# STM32WBA50xx register map
File version: 1.0
Registers are 32-bit, read-write, reset 0x0 unless marked. A register's access mark holds for its fields unless they carry their own. Offsets are from the block's base; [hi:lo] are bit positions; lines under a group give offsets from that group; {n}, {i} and the like mark numbered series; 'fields as' and 'values as' point back to an identical list.

## CRC — CRC calculation unit
Base 0x40023000
0x00 DR — CRC Data register
  [31:0] DR — Data register bits
0x04 IDR — CRC Independent data register
  [31:0] IDR — General-purpose 32-bits data register bits
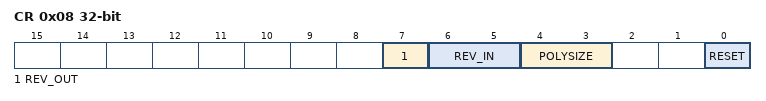
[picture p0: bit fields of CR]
0x08 CR — CRC Control register
  [7] REV_OUT — REV_OUT Reverse Output Data bits
    0=NONE (Output Data bit order not affected); 1=BIT (Output Data bit reversal done by bit)
  [6:5] REV_IN — REV_IN Reverse Input Data bits
    0=NONE (Input Data bit order not affected); 1=BYTE (Input Data bit reversal done by byte); 2=HALFWORD (Input Data bit reversal done by half-word); 3=WORD (Input Data bit reversal done by word)
  [4:3] POLYSIZE — Polynomial size bits
    0=POLYLENGTH_32B (32 bits Polynomial size); 1=POLYLENGTH_16B (16 bits Polynomial size); 2=POLYLENGTH_8B (8 bits Polynomial size); 3=POLYLENGTH_7B (7 bits Polynomial size)
  [0] RESET — RESET the CRC computation unit bit
0x10 INIT — Initial CRC value register
  [31:0] INIT — Initial CRC value bits
0x14 POL — CRC polynomial register
  [31:0] POL — Coefficients of the polynomial

## TSC
Base 0x40024000
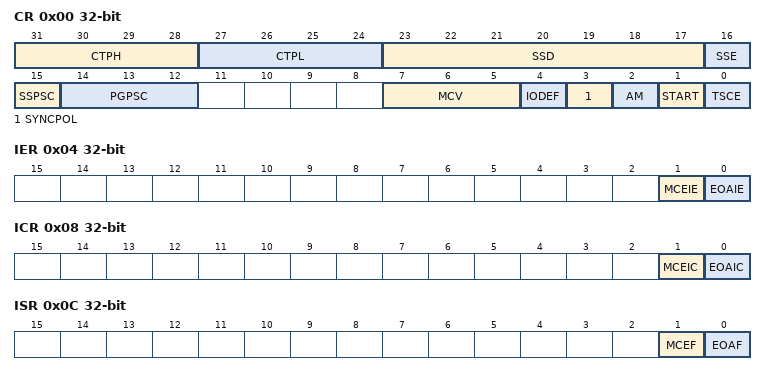
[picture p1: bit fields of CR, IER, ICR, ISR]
0x00 CR — TSC Control register
  [31:28] CTPH — CTPH[3:0] bits (Charge Transfer pulse high)
  [27:24] CTPL — CTPL[3:0] bits (Charge Transfer pulse low)
  [23:17] SSD — SSD[6:0] bits (Spread Spectrum Deviation)
  [16] SSE — Spread Spectrum Enable
  [15] SSPSC — Spread Spectrum Prescaler
  [14:12] PGPSC — PGPSC[2:0] bits (Pulse Generator Prescaler)
  [7:5] MCV — MCV[2:0] bits (Max Count Value)
  [4] IODEF — IO default mode
  [3] SYNCPOL — Synchronization pin polarity
  [2] AM — Acquisition mode
  [1] START — Start acquisition
  [0] TSCE — Touch sensing controller enable
0x04 IER — TSC Interrupt Enable register
  [1] MCEIE — Max count error interrupt enable
  [0] EOAIE — End of acquisition interrupt enable
0x08 ICR — TSC Interrupt Control register
  [1] MCEIC — Max count error interrupt clear
  [0] EOAIC — End of acquisition interrupt clear
0x0C ISR — TSC Interrupt Status register
  [1] MCEF — Max count error flag
  [0] EOAF — End of acquisition flag
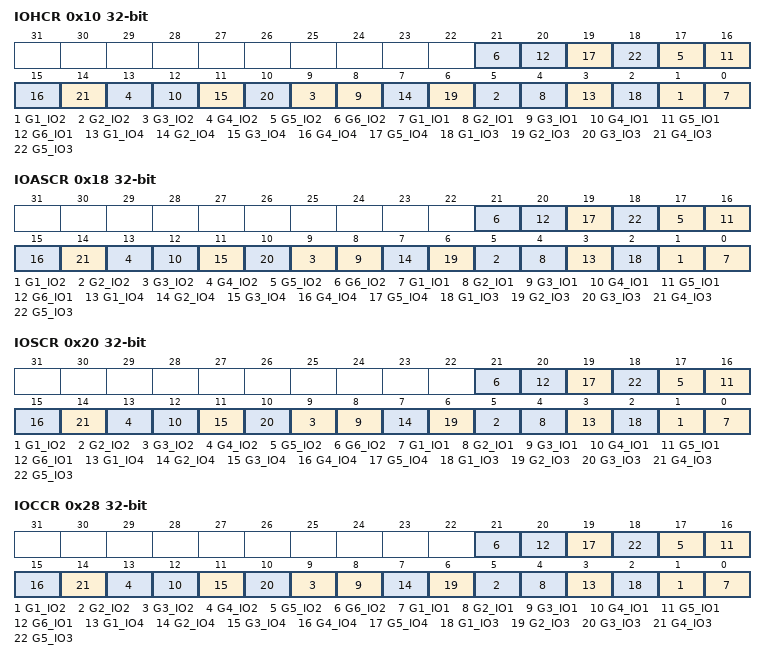
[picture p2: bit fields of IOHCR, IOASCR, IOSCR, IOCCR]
0x10 IOHCR — TSC I/O hysteresis control register
  [4n-3] G{n}_IO2 (n=1..6) — GROUP{n}_IO2 schmitt trigger hysteresis mode
  [4n-4] G{n}_IO1 (n=1..6) — GROUP{n}_IO1 schmitt trigger hysteresis mode
  [4n-1] G{n}_IO4 (n=1..5) — GROUP{n}_IO4 schmitt trigger hysteresis mode
  [4n-2] G{n}_IO3 (n=1..5) — GROUP{n}_IO3 schmitt trigger hysteresis mode
0x18 IOASCR — TSC I/O analog switch control register
  [4n-3] G{n}_IO2 (n=1..6) — GROUP{n}_IO2 analog switch enable
  [4n-4] G{n}_IO1 (n=1..6) — GROUP{n}_IO1 analog switch enable
  [4n-1] G{n}_IO4 (n=1..5) — GROUP{n}_IO4 analog switch enable
  [4n-2] G{n}_IO3 (n=1..5) — GROUP{n}_IO3 analog switch enable
0x20 IOSCR — TSC I/O sampling control register
  [4n-3] G{n}_IO2 (n=1..6) — GROUP{n}_IO2 sampling mode
  [4n-4] G{n}_IO1 (n=1..6) — GROUP{n}_IO1 sampling mode
  [4n-1] G{n}_IO4 (n=1..5) — GROUP{n}_IO4 sampling mode
  [4n-2] G{n}_IO3 (n=1..5) — GROUP{n}_IO3 sampling mode
0x28 IOCCR — TSC I/O channel control register
  [4n-3] G{n}_IO2 (n=1..6) — GROUP{n}_IO2 channel mode
  [4n-4] G{n}_IO1 (n=1..6) — GROUP{n}_IO1 channel mode
  [4n-1] G{n}_IO4 (n=1..5) — GROUP{n}_IO4 channel mode
  [4n-2] G{n}_IO3 (n=1..5) — GROUP{n}_IO3 channel mode
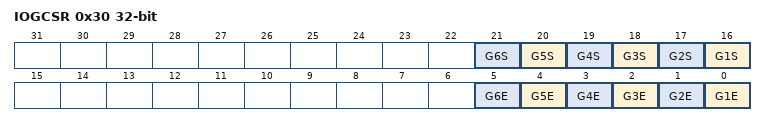
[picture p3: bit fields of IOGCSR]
0x30 IOGCSR — TSC I/O group control status register
  [n+15] G{n}S (n=1..6) — Analog IO GROUP{n} status
  [n-1] G{n}E (n=1..6) — Analog IO GROUP{n} enable
{0x30+4i} IOG{i}CR (i=1..6) — TSC I/O group x counter register
  [13:0] CNT — CNT[13:0] bits (Counter value)

## RAMCFG
Base 0x40026000
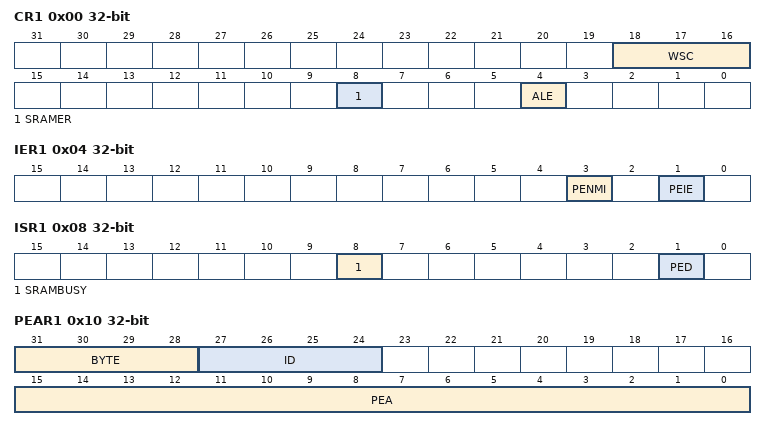
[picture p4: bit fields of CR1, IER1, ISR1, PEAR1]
0x00 CR1 — Control Register
  [18:16] WSC — WSC[18:16] Wait State Configuration field
  [8] SRAMER — Start Erase
  [4] ALE — Address Latching Enable
0x04 IER1 — Interrupt enable register
  [3] PENMI — Parity error NMI
  [1] PEIE — Parity error interrupt enable
0x08 ISR1 — Interrupt status register
  [8] SRAMBUSY — SRAM busy with erase operation
  [1] PED — Parity error detected
0x10 PEAR1 — Parity error address register
  [31:28] BYTE — Byte parity error flag
  [27:24] ID — Parity error AHB bus master ID
  [15:0] PEA — Parity error SRAM word aligned address offset
0x14 ICR1 — Interrupt clear register
  [1] CPED — Clear parity error detect bit
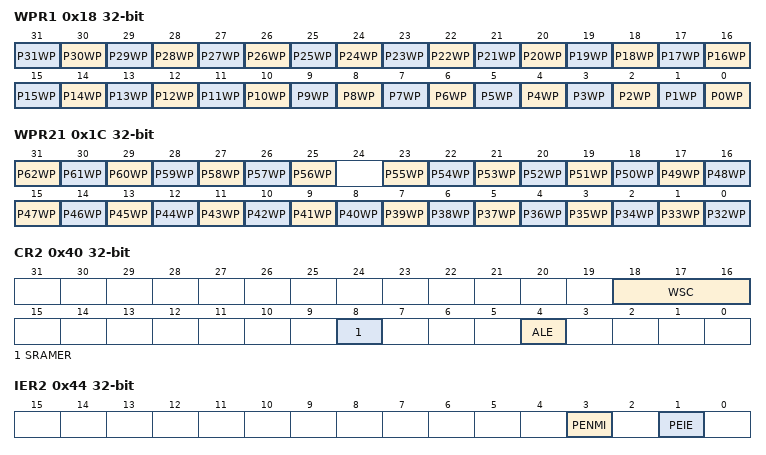
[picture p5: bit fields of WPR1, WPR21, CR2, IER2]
0x18 WPR1 — Write protection register 1
  [n] P{n}WP (n=0..31) — Write Protection Page {n:02}
0x1C WPR21 — Write protection register 2
  [n-31] P{n}WP (n=56..62) — Write Protection Page {n}
  [n-32] P{n}WP (n=32..55) — Write Protection Page {n}
0x28 ERKEYR1 — Erase key register
  [7:0] ERASEKEY — Erase write protection key
0x40 CR2 — Control Register
  fields as CR1
0x44 IER2 — Interrupt enable register
  fields as IER1
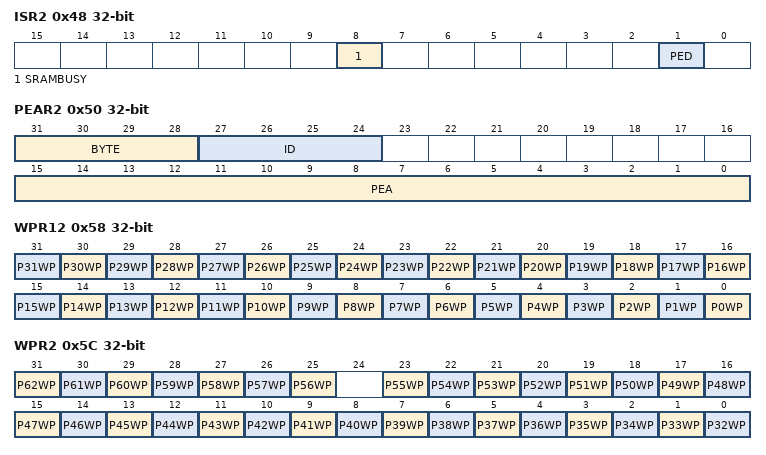
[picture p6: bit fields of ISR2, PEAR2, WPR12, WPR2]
0x48 ISR2 — Interrupt status register
  fields as ISR1
0x50 PEAR2 — Parity error address register
  fields as PEAR1
0x54 ICR2 — Interrupt clear register
  [1] CPED — Clear parity error detect bit
0x58 WPR12 — Write protection register 1
  [n] P{n}WP (n=0..31) — Write Protection Page {n:02}
0x5C WPR2 — Write protection register 2
  fields as WPR21
0x68 ERKEYR2 — Erase key register
  [7:0] ERASEKEY — Erase write protection key
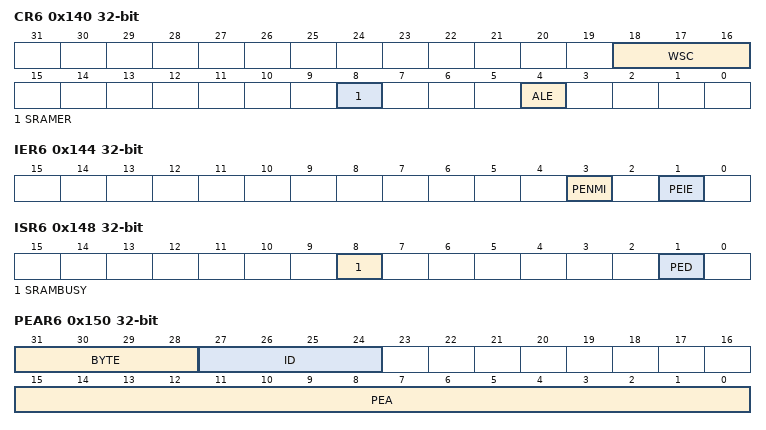
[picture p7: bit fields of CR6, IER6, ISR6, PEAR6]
0x140 CR6 — Control Register
  fields as CR1
0x144 IER6 — Interrupt enable register
  fields as IER1
0x148 ISR6 — Interrupt status register
  fields as ISR1
0x150 PEAR6 — Parity error address register
  fields as PEAR1
0x154 ICR6 — Interrupt clear register
  [1] CPED — Clear parity error detect bit
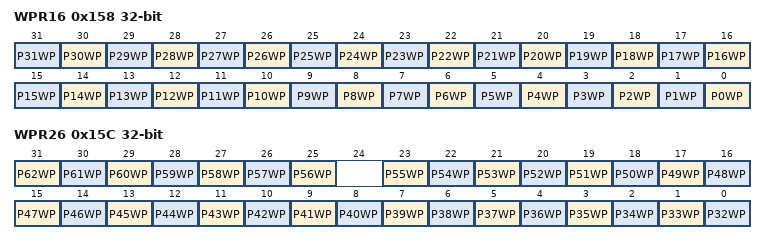
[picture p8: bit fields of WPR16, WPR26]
0x158 WPR16 — Write protection register 1
  [n] P{n}WP (n=0..31) — Write Protection Page {n:02}
0x15C WPR26 — Write protection register 2
  fields as WPR21
0x168 ERKEYR6 — Erase key register
  [7:0] ERASEKEY — Erase write protection key
